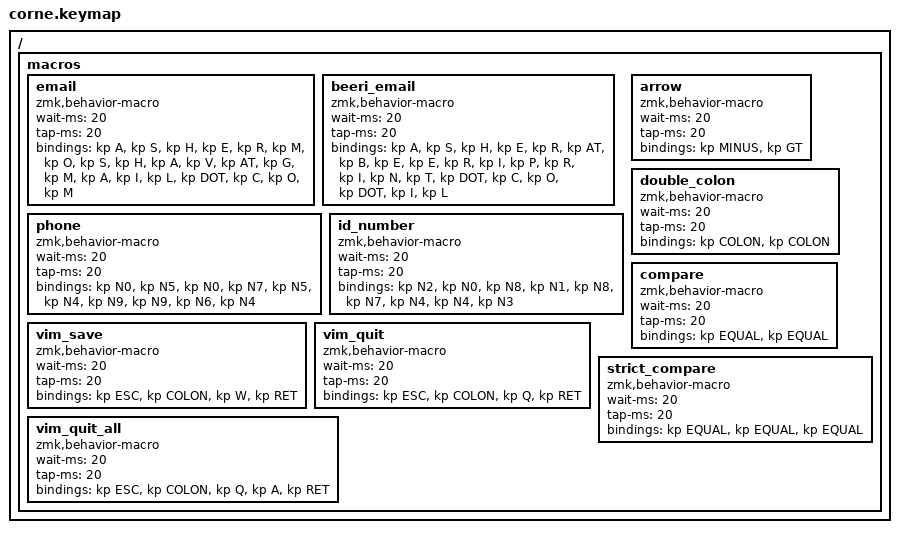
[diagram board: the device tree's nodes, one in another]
#include <dt-bindings/zmk/keys.h>
#include <dt-bindings/zmk/bt.h>
#include <dt-bindings/zmk/ext_power.h>
#include <behaviors.dtsi>
// Copyright 2021 Manna Harbour
// https://github.com/manna-harbour/miryoku

/ {
        macros {
        email: email {
            compatible = "zmk,behavior-macro";
            #binding-cells = <0>;
            wait-ms = <20>;
            tap-ms = <20>;
            bindings = <&kp A &kp S &kp H &kp E &kp R &kp M &kp O &kp S &kp H &kp A &kp V>
              , <&kp AT>
              , <&kp G &kp M &kp A &kp I &kp L>
              , <&kp DOT>
              , <&kp C &kp O &kp M>
              ;        };

        beeri_email: beeri_email {
            compatible = "zmk,behavior-macro";
            #binding-cells = <0>;
            wait-ms = <20>;
            tap-ms = <20>;
            bindings
              = <&kp A &kp S &kp H &kp E &kp R>
              , <&kp AT>
              , <&kp B &kp E &kp E &kp R &kp I &kp P &kp R &kp I &kp N &kp T>
              , <&kp DOT>
              , <&kp C &kp O>
              , <&kp DOT>
              , <&kp I &kp L>
              ;        };

        phone: phone {
            compatible = "zmk,behavior-macro";
            #binding-cells = <0>;
            wait-ms = <20>;
            tap-ms = <20>;
            bindings
              = <&kp N0 &kp N5 &kp N0 &kp N7 &kp N5 &kp N4 &kp N9 &kp N9 &kp N6 &kp N4>
              ;        };

        id_number: id_number {
            compatible = "zmk,behavior-macro";
            #binding-cells = <0>;
            wait-ms = <20>;
            tap-ms = <20>;
            bindings
              = <&kp N2 &kp N0 &kp N8 &kp N1 &kp N8 &kp N7 &kp N4 &kp N4 &kp N3>
              ;        };

        vim_save: vim_save {
            compatible = "zmk,behavior-macro";
            #binding-cells = <0>;
            wait-ms = <20>;
            tap-ms = <20>;
            bindings
              = <&kp ESC &kp COLON &kp W &kp RET>
              ;        };

        vim_quit: vim_quit {
            compatible = "zmk,behavior-macro";
            #binding-cells = <0>;
            wait-ms = <20>;
            tap-ms = <20>;
            bindings
              = <&kp ESC &kp COLON &kp Q &kp RET>
              ;        };

        vim_quit_all: vim_quit_all {
            compatible = "zmk,behavior-macro";
            #binding-cells = <0>;
            wait-ms = <20>;
            tap-ms = <20>;
            bindings
              = <&kp ESC &kp COLON &kp Q &kp A &kp RET>
              ;        };

        arrow: arrow {
            compatible = "zmk,behavior-macro";
            #binding-cells = <0>;
            wait-ms = <20>;
            tap-ms = <20>;
            bindings
              = <&kp MINUS &kp GT>
              ;        };

        double_colon: double_colon {
            compatible = "zmk,behavior-macro";
            #binding-cells = <0>;
            wait-ms = <20>;
            tap-ms = <20>;
            bindings
              = <&kp COLON &kp COLON>
              ;        };

        compare: compare {
            compatible = "zmk,behavior-macro";
            #binding-cells = <0>;
            wait-ms = <20>;
            tap-ms = <20>;
            bindings
              = <&kp EQUAL &kp EQUAL>
              ;        };

        strict_compare: strict_compare {
            compatible = "zmk,behavior-macro";
            #binding-cells = <0>;
            wait-ms = <20>;
            tap-ms = <20>;
            bindings
              = <&kp EQUAL &kp EQUAL &kp EQUAL>
              ;        };
  };
};

#include "../miryoku/custom_config.h"
#include "../miryoku/mapping/42/corne.h"
#include "../miryoku/miryoku.dtsi"
